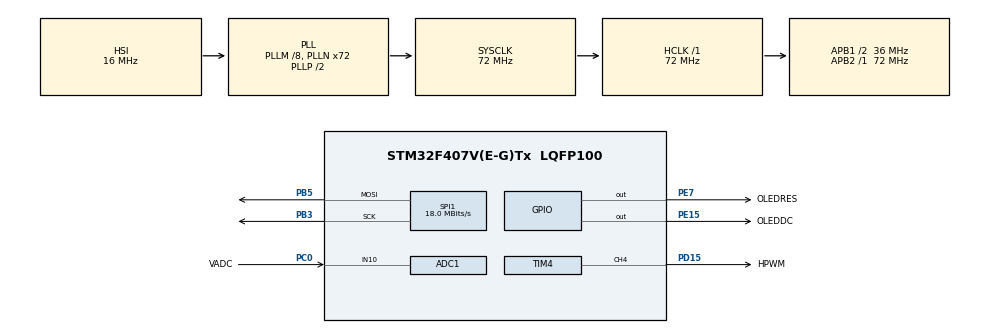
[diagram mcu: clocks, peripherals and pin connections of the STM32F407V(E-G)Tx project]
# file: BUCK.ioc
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ADC1.Channel-0\#ChannelRegularConversion=ADC_CHANNEL_10
ADC1.NbrOfConversionFlag=1
ADC1.Rank-0\#ChannelRegularConversion=1
ADC1.SamplingTime-0\#ChannelRegularConversion=ADC_SAMPLETIME_3CYCLES
ADC1.master=1
Mcu.Family=STM32F4
Mcu.Name=STM32F407V(E-G)Tx
Mcu.Package=LQFP100
NVIC.PriorityGroup=NVIC_PRIORITYGROUP_4
NVIC.TIM3_IRQn=true\:0\:0\:false\:false\:true\:true\:true
PA13.Mode=Serial_Wire
PA13.Signal=SYS_JTMS-SWDIO
PA14.Mode=Serial_Wire
PA14.Signal=SYS_JTCK-SWCLK
PB3.Mode=TX_Only_Simplex_Unidirect_Master
PB3.Signal=SPI1_SCK
PB5.Mode=TX_Only_Simplex_Unidirect_Master
PB5.Signal=SPI1_MOSI
PC0.GPIO_Label=VADC
PC0.Signal=ADCx_IN10
PD15.GPIO_Label=HPWM
PD15.GPIO_ModeDefaultPP=GPIO_MODE_AF_PP
PD15.GPIO_PuPd=GPIO_NOPULL
PD15.GPIO_Speed=GPIO_SPEED_FREQ_VERY_HIGH
PD15.Signal=S_TIM4_CH4
PE15.GPIO_Label=OLEDDC
PE15.GPIO_Speed=GPIO_SPEED_FREQ_VERY_HIGH
PE15.Signal=GPIO_Output
PE7.GPIO_Label=OLEDRES
PE7.GPIO_Speed=GPIO_SPEED_FREQ_VERY_HIGH
PE7.Signal=GPIO_Output
ProjectManager.HeapSize=0x200
ProjectManager.StackSize=0x400
ProjectManager.TargetToolchain=MDK-ARM V5.27
RCC.48MHZClocksFreq_Value=36000000
RCC.AHBFreq_Value=72000000
RCC.APB1CLKDivider=RCC_HCLK_DIV2
RCC.APB1Freq_Value=36000000
RCC.APB1TimFreq_Value=72000000
RCC.APB2Freq_Value=72000000
RCC.APB2TimFreq_Value=72000000
RCC.CortexFreq_Value=72000000
RCC.HCLKFreq_Value=72000000
RCC.HSE_VALUE=25000000
RCC.HSI_VALUE=16000000
RCC.LSE_VALUE=32768
RCC.PLLM=8
RCC.PLLN=72
RCC.SYSCLKFreq_VALUE=72000000
RCC.SYSCLKSource=RCC_SYSCLKSOURCE_PLLCLK
RCC.VCOOutputFreq_Value=144000000
SH.ADCx_IN10.0=ADC1_IN10,IN10
SH.S_TIM4_CH4.0=TIM4_CH4,PWM Generation4 CH4
SPI1.BaudRatePrescaler=SPI_BAUDRATEPRESCALER_4
SPI1.CalculateBaudRate=18.0 MBits/s
SPI1.Direction=SPI_DIRECTION_2LINES
SPI1.Mode=SPI_MODE_MASTER
SPI1.VirtualType=VM_MASTER
TIM3.AutoReloadPreload=TIM_AUTORELOAD_PRELOAD_ENABLE
TIM3.Period=799
TIM3.Prescaler=3599
TIM4.AutoReloadPreload=TIM_AUTORELOAD_PRELOAD_ENABLE
TIM4.Channel-PWM\ Generation4\ CH4=TIM_CHANNEL_4
TIM4.Period=359
TIM4.Prescaler=1
TIM4.Pulse-PWM\ Generation4\ CH4=179
VP_TIM3_VS_ClockSourceINT.Mode=Internal
VP_TIM4_VS_ClockSourceINT.Mode=Internal
board=custom

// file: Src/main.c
/* USER CODE BEGIN Header */
/**
  ******************************************************************************
  * @file           : main.c
  * @brief          : Main program body
  ******************************************************************************
  * @attention
  *
  * <h2><center>&copy; Copyright (c) 2019 STMicroelectronics.
  * All rights reserved.</center></h2>
  *
  * This software component is licensed by ST under BSD 3-Clause license,
  * the "License"; You may not use this file except in compliance with the
  * License. You may obtain a copy of the License at:
  *                        opensource.org/licenses/BSD-3-Clause
  *
  ******************************************************************************
  */
/* USER CODE END Header */

#include "main.h"
#include "adc.h"
#include "spi.h"
#include "tim.h"
#include "gpio.h"

/* USER CODE BEGIN PV */
uint16_t i;
/* USER CODE END PV */

void SystemClock_Config(void);

int main(void)
{

  /* MCU Configuration--------------------------------------------------------*/

  /* Reset of all peripherals, Initializes the Flash interface and the Systick. */
  HAL_Init();

  /* Configure the system clock */
  SystemClock_Config();

  /* Initialize all configured peripherals */
  MX_GPIO_Init();
  MX_TIM4_Init();
  MX_ADC1_Init();
  MX_SPI1_Init();
  MX_TIM3_Init();
  /* USER CODE BEGIN 2 */
	OLED_Init();
	HAL_TIM_PWM_Start(&htim4,TIM_CHANNEL_4);
	HAL_TIM_Base_Start_IT(&htim3);
	//OLED1_ShowString(0,0,"OK");
  /* USER CODE END 2 */

  /* Infinite loop */
  while (1)
  {

  }
}

void SystemClock_Config(void)
{
  RCC_OscInitTypeDef RCC_OscInitStruct = {0};
  RCC_ClkInitTypeDef RCC_ClkInitStruct = {0};

  /** Configure the main internal regulator output voltage
  */
  __HAL_RCC_PWR_CLK_ENABLE();
  __HAL_PWR_VOLTAGESCALING_CONFIG(PWR_REGULATOR_VOLTAGE_SCALE1);
  /** Initializes the CPU, AHB and APB busses clocks
  */
  RCC_OscInitStruct.OscillatorType = RCC_OSCILLATORTYPE_HSI;
  RCC_OscInitStruct.HSIState = RCC_HSI_ON;
  RCC_OscInitStruct.HSICalibrationValue = RCC_HSICALIBRATION_DEFAULT;
  RCC_OscInitStruct.PLL.PLLState = RCC_PLL_ON;
  RCC_OscInitStruct.PLL.PLLSource = RCC_PLLSOURCE_HSI;
  RCC_OscInitStruct.PLL.PLLM = 8;
  RCC_OscInitStruct.PLL.PLLN = 72;
  RCC_OscInitStruct.PLL.PLLP = RCC_PLLP_DIV2;
  RCC_OscInitStruct.PLL.PLLQ = 4;
  if (HAL_RCC_OscConfig(&RCC_OscInitStruct) != HAL_OK)
  {
    Error_Handler();
  }
  /** Initializes the CPU, AHB and APB busses clocks
  */
  RCC_ClkInitStruct.ClockType = RCC_CLOCKTYPE_HCLK|RCC_CLOCKTYPE_SYSCLK
                              |RCC_CLOCKTYPE_PCLK1|RCC_CLOCKTYPE_PCLK2;
  RCC_ClkInitStruct.SYSCLKSource = RCC_SYSCLKSOURCE_PLLCLK;
  RCC_ClkInitStruct.AHBCLKDivider = RCC_SYSCLK_DIV1;
  RCC_ClkInitStruct.APB1CLKDivider = RCC_HCLK_DIV2;
  RCC_ClkInitStruct.APB2CLKDivider = RCC_HCLK_DIV1;

  if (HAL_RCC_ClockConfig(&RCC_ClkInitStruct, FLASH_LATENCY_2) != HAL_OK)
  {
    Error_Handler();
  }
}

/* USER CODE BEGIN 4 */
void HAL_TIM_PeriodElapsedCallback(TIM_HandleTypeDef *htim)
{
	UNUSED(htim);
	if(htim==&htim3)
	{
		++i;
		if(i>10000)
			i=0;
		OLED1_ShowString(0,0,"OK");
		OLED1_ShowNum(0,2,i,4,0);//显示数字mode=1,补零，num有符号32位
	}
}
/* USER CODE END 4 */

void Error_Handler(void)
{
}

/************************ (C) COPYRIGHT STMicroelectronics *****END OF FILE****/
